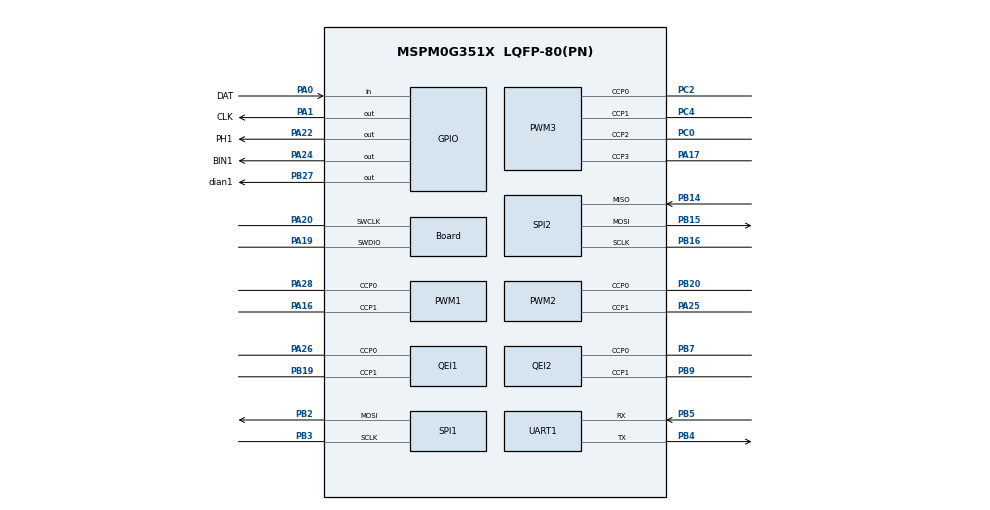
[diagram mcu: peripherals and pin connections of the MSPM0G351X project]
/**
 *
 * @cliArgs --device "MSPM0G351X" --part "Default" --package "LQFP-80(PN)" --product "mspm0_sdk@2.11.00.07"
 * @versions {"tool":"1.28.0+4712"}
 */

/**
 * Import the modules used in this configuration.
 */
const ADC12  = scripting.addModule("/ti/driverlib/ADC12", {}, false);
const ADC121 = ADC12.addInstance();
const GPIO   = scripting.addModule("/ti/driverlib/GPIO", {}, false);
const GPIO1  = GPIO.addInstance();
const GPIO2  = GPIO.addInstance();
const GPIO3  = GPIO.addInstance();
const GPIO4  = GPIO.addInstance();
const GPIO5  = GPIO.addInstance();
const GPIO6  = GPIO.addInstance();
const GPIO7  = GPIO.addInstance();
const GPIO8  = GPIO.addInstance();
const PWM    = scripting.addModule("/ti/driverlib/PWM", {}, false);
const PWM1   = PWM.addInstance();
const PWM2   = PWM.addInstance();
const PWM3   = PWM.addInstance();
const QEI    = scripting.addModule("/ti/driverlib/QEI", {}, false);
const QEI1   = QEI.addInstance();
const QEI2   = QEI.addInstance();
const SPI    = scripting.addModule("/ti/driverlib/SPI", {}, false);
const SPI1   = SPI.addInstance();
const SPI2   = SPI.addInstance();
const SYSCTL = scripting.addModule("/ti/driverlib/SYSCTL");
const UART   = scripting.addModule("/ti/driverlib/UART", {}, false);
const UART1  = UART.addInstance();

/**
 * Write custom configuration values to the imported modules.
 */
const divider9       = system.clockTree["UDIV"];
divider9.divideValue = 2;

const multiplier2         = system.clockTree["PLL_QDIV"];
multiplier2.multiplyValue = 5;

const mux8       = system.clockTree["HSCLKMUX"];
mux8.inputSelect = "HSCLKMUX_SYSPLL0";

ADC121.sampClkDiv                        = "DL_ADC12_CLOCK_DIVIDE_4";
ADC121.samplingOperationMode             = "sequence";
ADC121.endAdd                            = 1;
ADC121.$name                             = "ADC1";
ADC121.sampleMode                        = "DL_ADC12_SAMPLING_SOURCE_MANUAL";
ADC121.adcMem1chansel                    = "DL_ADC12_INPUT_CHAN_4";
ADC121.adcMem1_name                      = "DRC8873_ADC1";
ADC121.adcMem0_name                      = "DRC8873_ADC0";
ADC121.adcPin0Config.hideOutputInversion = scripting.forceWrite(false);
ADC121.adcPin0Config.$name               = "ti_driverlib_gpio_GPIOPinGeneric25";
ADC121.peripheral.$assign                = "ADC1";
ADC121.peripheral.adcPin0.$assign        = "PA15";
ADC121.adcPin4Config.$name               = "ti_driverlib_gpio_GPIOPinGeneric27";

const Board                       = scripting.addModule("/ti/driverlib/Board", {}, false);
Board.peripheral.$assign          = "DEBUGSS";
Board.peripheral.swclkPin.$assign = "PA20";
Board.peripheral.swdioPin.$assign = "PA19";

GPIO1.$name                                 = "TFT";
GPIO1.associatedPins.create(4);
GPIO1.associatedPins[0].assignedPort        = "PORTC";
GPIO1.associatedPins[0].assignedPin         = "8";
GPIO1.associatedPins[0].assignedPortSegment = "Lower";
GPIO1.associatedPins[0].initialValue        = "SET";
GPIO1.associatedPins[0].ioStructure         = "SD";
GPIO1.associatedPins[0].$name               = "TFT_DC";
GPIO1.associatedPins[1].assignedPort        = "PORTC";
GPIO1.associatedPins[1].assignedPin         = "9";
GPIO1.associatedPins[1].assignedPortSegment = "Lower";
GPIO1.associatedPins[1].ioStructure         = "SD";
GPIO1.associatedPins[1].initialValue        = "SET";
GPIO1.associatedPins[1].$name               = "TFT_CS";
GPIO1.associatedPins[2].assignedPort        = "PORTB";
GPIO1.associatedPins[2].assignedPin         = "23";
GPIO1.associatedPins[2].initialValue        = "SET";
GPIO1.associatedPins[2].ioStructure         = "SD";
GPIO1.associatedPins[2].$name               = "TFT_RES";
GPIO1.associatedPins[3].initialValue        = "SET";
GPIO1.associatedPins[3].ioStructure         = "SD";
GPIO1.associatedPins[3].assignedPort        = "PORTA";
GPIO1.associatedPins[3].assignedPin         = "30";
GPIO1.associatedPins[3].$name               = "TFT_BLK";

GPIO2.$name                               = "key";
GPIO2.associatedPins.create(5);
GPIO2.associatedPins[0].$name             = "key0";
GPIO2.associatedPins[0].direction         = "INPUT";
GPIO2.associatedPins[0].assignedPort      = "PORTB";
GPIO2.associatedPins[0].assignedPin       = "29";
GPIO2.associatedPins[0].ioStructure       = "SD";
GPIO2.associatedPins[0].interruptEn       = true;
GPIO2.associatedPins[0].interruptPriority = "1";
GPIO2.associatedPins[0].polarity          = "FALL";
GPIO2.associatedPins[1].$name             = "key1";
GPIO2.associatedPins[1].direction         = "INPUT";
GPIO2.associatedPins[1].ioStructure       = "SD";
GPIO2.associatedPins[1].assignedPort      = "PORTB";
GPIO2.associatedPins[1].assignedPin       = "30";
GPIO2.associatedPins[1].interruptEn       = true;
GPIO2.associatedPins[1].interruptPriority = "1";
GPIO2.associatedPins[1].polarity          = "FALL";
GPIO2.associatedPins[2].$name             = "key2";
GPIO2.associatedPins[2].direction         = "INPUT";
GPIO2.associatedPins[2].ioStructure       = "SD";
GPIO2.associatedPins[2].assignedPort      = "PORTC";
GPIO2.associatedPins[2].assignedPin       = "6";
GPIO2.associatedPins[2].interruptEn       = true;
GPIO2.associatedPins[2].interruptPriority = "1";
GPIO2.associatedPins[2].polarity          = "FALL";
GPIO2.associatedPins[3].$name             = "key3";
GPIO2.associatedPins[3].direction         = "INPUT";
GPIO2.associatedPins[3].ioStructure       = "SD";
GPIO2.associatedPins[3].assignedPort      = "PORTC";
GPIO2.associatedPins[3].assignedPin       = "7";
GPIO2.associatedPins[3].interruptEn       = true;
GPIO2.associatedPins[3].interruptPriority = "1";
GPIO2.associatedPins[3].polarity          = "FALL";
GPIO2.associatedPins[4].$name             = "user_key";
GPIO2.associatedPins[4].direction         = "INPUT";
GPIO2.associatedPins[4].assignedPort      = "PORTB";
GPIO2.associatedPins[4].assignedPin       = "31";
GPIO2.associatedPins[4].interruptEn       = true;
GPIO2.associatedPins[4].interruptPriority = "1";
GPIO2.associatedPins[4].polarity          = "FALL";

GPIO3.$name                          = "imuInt";
GPIO3.associatedPins[0].$name        = "CS";
GPIO3.associatedPins[0].assignedPort = "PORTB";
GPIO3.associatedPins[0].assignedPin  = "13";
GPIO3.associatedPins[0].ioStructure  = "SD";
GPIO3.associatedPins[0].initialValue = "SET";

GPIO4.$name                          = "TB6612";
GPIO4.associatedPins.create(4);
GPIO4.associatedPins[0].$name        = "AIN2";
GPIO4.associatedPins[0].ioStructure  = "SD";
GPIO4.associatedPins[0].assignedPort = "PORTB";
GPIO4.associatedPins[0].assignedPin  = "22";
GPIO4.associatedPins[1].$name        = "AIN1";
GPIO4.associatedPins[1].ioStructure  = "SD";
GPIO4.associatedPins[1].assignedPort = "PORTB";
GPIO4.associatedPins[1].assignedPin  = "28";
GPIO4.associatedPins[2].$name        = "BIN1";
GPIO4.associatedPins[2].ioStructure  = "SD";
GPIO4.associatedPins[2].assignedPort = "PORTA";
GPIO4.associatedPins[2].assignedPin  = "24";
GPIO4.associatedPins[2].pin.$assign  = "PA24";
GPIO4.associatedPins[3].$name        = "BIN2";
GPIO4.associatedPins[3].assignedPort = "PORTA";
GPIO4.associatedPins[3].assignedPin  = "13";

GPIO5.$name                          = "dianci";
GPIO5.associatedPins.create(2);
GPIO5.associatedPins[0].ioStructure  = "SD";
GPIO5.associatedPins[0].$name        = "dian1";
GPIO5.associatedPins[0].assignedPin  = "27";
GPIO5.associatedPins[0].assignedPort = "PORTB";
GPIO5.associatedPins[0].pin.$assign  = "PB27";
GPIO5.associatedPins[1].$name        = "dian2";
GPIO5.associatedPins[1].assignedPort = "PORTB";
GPIO5.associatedPins[1].assignedPin  = "26";

GPIO6.$name                          = "buzzer";
GPIO6.associatedPins[0].$name        = "PIN_0";
GPIO6.associatedPins[0].ioStructure  = "SD";
GPIO6.associatedPins[0].assignedPort = "PORTB";
GPIO6.associatedPins[0].assignedPin  = "1";

GPIO7.$name                          = "DRV8873HPWPT";
GPIO7.associatedPins.create(2);
GPIO7.associatedPins[0].$name        = "PH1";
GPIO7.associatedPins[0].ioStructure  = "SD";
GPIO7.associatedPins[0].assignedPort = "PORTA";
GPIO7.associatedPins[0].pin.$assign  = "PA22";
GPIO7.associatedPins[1].$name        = "PH2";
GPIO7.associatedPins[1].ioStructure  = "SD";
GPIO7.associatedPins[1].assignedPort = "PORTB";
GPIO7.associatedPins[1].assignedPin  = "18";

GPIO8.$name                          = "graySerial";
GPIO8.associatedPins.create(2);
GPIO8.associatedPins[0].$name        = "CLK";
GPIO8.associatedPins[0].initialValue = "SET";
GPIO8.associatedPins[0].assignedPin  = "1";
GPIO8.associatedPins[0].assignedPort = "PORTA";
GPIO8.associatedPins[0].pin.$assign  = "PA1";
GPIO8.associatedPins[1].$name        = "DAT";
GPIO8.associatedPins[1].direction    = "INPUT";
GPIO8.associatedPins[1].assignedPort = "PORTA";
GPIO8.associatedPins[1].assignedPin  = "0";
GPIO8.associatedPins[1].pin.$assign  = "PA0";

PWM1.clockPrescale                      = 8;
PWM1.timerCount                         = 400;
PWM1.$name                              = "TB6612PWM";
PWM1.pwmMode                            = "EDGE_ALIGN_UP";
PWM1.peripheral.$assign                 = "TIMA1";
PWM1.peripheral.ccp0Pin.$assign         = "PA28";
PWM1.peripheral.ccp1Pin.$assign         = "PA16";
PWM1.PWM_CHANNEL_0.$name                = "ti_driverlib_pwm_PWMTimerCC4";
PWM1.PWM_CHANNEL_1.$name                = "ti_driverlib_pwm_PWMTimerCC5";
PWM1.ccp0PinConfig.direction            = scripting.forceWrite("OUTPUT");
PWM1.ccp0PinConfig.hideOutputInversion  = scripting.forceWrite(false);
PWM1.ccp0PinConfig.onlyInternalResistor = scripting.forceWrite(false);
PWM1.ccp0PinConfig.passedPeripheralType = scripting.forceWrite("Digital");
PWM1.ccp0PinConfig.$name                = "ti_driverlib_gpio_GPIOPinGeneric21";
PWM1.ccp1PinConfig.direction            = scripting.forceWrite("OUTPUT");
PWM1.ccp1PinConfig.hideOutputInversion  = scripting.forceWrite(false);
PWM1.ccp1PinConfig.onlyInternalResistor = scripting.forceWrite(false);
PWM1.ccp1PinConfig.passedPeripheralType = scripting.forceWrite("Digital");
PWM1.ccp1PinConfig.$name                = "ti_driverlib_gpio_GPIOPinGeneric22";

PWM2.$name                              = "DRV8873";
PWM2.pwmMode                            = "EDGE_ALIGN_UP";
PWM2.peripheral.ccp0Pin.$assign         = "PB20";
PWM2.peripheral.ccp1Pin.$assign         = "PA25";
PWM2.PWM_CHANNEL_0.$name                = "ti_driverlib_pwm_PWMTimerCC6";
PWM2.PWM_CHANNEL_1.$name                = "ti_driverlib_pwm_PWMTimerCC7";
PWM2.ccp0PinConfig.direction            = scripting.forceWrite("OUTPUT");
PWM2.ccp0PinConfig.hideOutputInversion  = scripting.forceWrite(false);
PWM2.ccp0PinConfig.onlyInternalResistor = scripting.forceWrite(false);
PWM2.ccp0PinConfig.passedPeripheralType = scripting.forceWrite("Digital");
PWM2.ccp0PinConfig.$name                = "ti_driverlib_gpio_GPIOPinGeneric23";
PWM2.ccp1PinConfig.direction            = scripting.forceWrite("OUTPUT");
PWM2.ccp1PinConfig.hideOutputInversion  = scripting.forceWrite(false);
PWM2.ccp1PinConfig.onlyInternalResistor = scripting.forceWrite(false);
PWM2.ccp1PinConfig.passedPeripheralType = scripting.forceWrite("Digital");
PWM2.ccp1PinConfig.$name                = "ti_driverlib_gpio_GPIOPinGeneric24";

PWM3.$name                              = "servo";
PWM3.ccIndex                            = [0,1,2,3];
PWM3.pwmMode                            = "EDGE_ALIGN_UP";
PWM3.clockPrescale                      = 79;
PWM3.timerCount                         = 20000;
PWM3.PWM_CHANNEL_0.$name                = "ti_driverlib_pwm_PWMTimerCC0";
PWM3.PWM_CHANNEL_1.$name                = "ti_driverlib_pwm_PWMTimerCC1";
PWM3.ccp0PinConfig.direction            = scripting.forceWrite("OUTPUT");
PWM3.ccp0PinConfig.hideOutputInversion  = scripting.forceWrite(false);
PWM3.ccp0PinConfig.onlyInternalResistor = scripting.forceWrite(false);
PWM3.ccp0PinConfig.passedPeripheralType = scripting.forceWrite("Digital");
PWM3.ccp0PinConfig.$name                = "ti_driverlib_gpio_GPIOPinGeneric13";
PWM3.ccp1PinConfig.direction            = scripting.forceWrite("OUTPUT");
PWM3.ccp1PinConfig.hideOutputInversion  = scripting.forceWrite(false);
PWM3.ccp1PinConfig.onlyInternalResistor = scripting.forceWrite(false);
PWM3.ccp1PinConfig.passedPeripheralType = scripting.forceWrite("Digital");
PWM3.ccp1PinConfig.$name                = "ti_driverlib_gpio_GPIOPinGeneric14";
PWM3.peripheral.$assign                 = "TIMA0";
PWM3.peripheral.ccp0Pin.$assign         = "PC2";
PWM3.peripheral.ccp1Pin.$assign         = "PC4";
PWM3.peripheral.ccp2Pin.$assign         = "PC0";
PWM3.peripheral.ccp3Pin.$assign         = "PA17";
PWM3.PWM_CHANNEL_2.$name                = "ti_driverlib_pwm_PWMTimerCC2";
PWM3.PWM_CHANNEL_3.$name                = "ti_driverlib_pwm_PWMTimerCC3";
PWM3.ccp2PinConfig.$name                = "ti_driverlib_gpio_GPIOPinGeneric15";
PWM3.ccp3PinConfig.$name                = "ti_driverlib_gpio_GPIOPinGeneric16";

QEI1.$name                              = "AB1";
QEI1.peripheral.$assign                 = "TIMG8";
QEI1.peripheral.ccp0Pin.$assign         = "PA26";
QEI1.peripheral.ccp1Pin.$assign         = "PB19";
QEI1.ccp0PinConfig.hideOutputInversion  = scripting.forceWrite(false);
QEI1.ccp0PinConfig.onlyInternalResistor = scripting.forceWrite(false);
QEI1.ccp0PinConfig.passedPeripheralType = scripting.forceWrite("Digital");
QEI1.ccp0PinConfig.$name                = "ti_driverlib_gpio_GPIOPinGeneric17";
QEI1.ccp1PinConfig.hideOutputInversion  = scripting.forceWrite(false);
QEI1.ccp1PinConfig.onlyInternalResistor = scripting.forceWrite(false);
QEI1.ccp1PinConfig.passedPeripheralType = scripting.forceWrite("Digital");
QEI1.ccp1PinConfig.$name                = "ti_driverlib_gpio_GPIOPinGeneric18";

QEI2.$name                              = "AB2";
QEI2.peripheral.ccp0Pin.$assign         = "PB7";
QEI2.peripheral.ccp1Pin.$assign         = "PB9";
QEI2.ccp0PinConfig.hideOutputInversion  = scripting.forceWrite(false);
QEI2.ccp0PinConfig.onlyInternalResistor = scripting.forceWrite(false);
QEI2.ccp0PinConfig.passedPeripheralType = scripting.forceWrite("Digital");
QEI2.ccp0PinConfig.$name                = "ti_driverlib_gpio_GPIOPinGeneric19";
QEI2.ccp1PinConfig.hideOutputInversion  = scripting.forceWrite(false);
QEI2.ccp1PinConfig.onlyInternalResistor = scripting.forceWrite(false);
QEI2.ccp1PinConfig.passedPeripheralType = scripting.forceWrite("Digital");
QEI2.ccp1PinConfig.$name                = "ti_driverlib_gpio_GPIOPinGeneric20";

SPI1.chipSelect                         = [];
SPI1.frameFormat                        = "MOTO3";
SPI1.$name                              = "TFT_SPI0";
SPI1.sclkPinConfig.direction            = scripting.forceWrite("OUTPUT");
SPI1.sclkPinConfig.onlyInternalResistor = scripting.forceWrite(false);
SPI1.sclkPinConfig.passedPeripheralType = scripting.forceWrite("Digital");
SPI1.sclkPinConfig.$name                = "ti_driverlib_gpio_GPIOPinGeneric0";
SPI1.mosiPinConfig.direction            = scripting.forceWrite("OUTPUT");
SPI1.mosiPinConfig.hideOutputInversion  = scripting.forceWrite(false);
SPI1.mosiPinConfig.onlyInternalResistor = scripting.forceWrite(false);
SPI1.mosiPinConfig.passedPeripheralType = scripting.forceWrite("Digital");
SPI1.mosiPinConfig.$name                = "ti_driverlib_gpio_GPIOPinGeneric1";
SPI1.misoPinConfig.onlyInternalResistor = scripting.forceWrite(false);
SPI1.misoPinConfig.passedPeripheralType = scripting.forceWrite("Digital");
SPI1.misoPinConfig.$name                = "ti_driverlib_gpio_GPIOPinGeneric2";
SPI1.peripheral.sclkPin.$assign         = "PB3";
SPI1.peripheral.mosiPin.$assign         = "PB2";

SPI2.$name                              = "IMU660RC";
SPI2.enableDMAEvent1                    = false;
SPI2.enableDMAEvent2                    = false;
SPI2.frameFormat                        = "MOTO3";
SPI2.sclkPinConfig.direction            = scripting.forceWrite("OUTPUT");
SPI2.sclkPinConfig.onlyInternalResistor = scripting.forceWrite(false);
SPI2.sclkPinConfig.passedPeripheralType = scripting.forceWrite("Digital");
SPI2.sclkPinConfig.$name                = "ti_driverlib_gpio_GPIOPinGeneric9";
SPI2.mosiPinConfig.direction            = scripting.forceWrite("OUTPUT");
SPI2.mosiPinConfig.hideOutputInversion  = scripting.forceWrite(false);
SPI2.mosiPinConfig.onlyInternalResistor = scripting.forceWrite(false);
SPI2.mosiPinConfig.passedPeripheralType = scripting.forceWrite("Digital");
SPI2.mosiPinConfig.$name                = "ti_driverlib_gpio_GPIOPinGeneric10";
SPI2.misoPinConfig.onlyInternalResistor = scripting.forceWrite(false);
SPI2.misoPinConfig.passedPeripheralType = scripting.forceWrite("Digital");
SPI2.misoPinConfig.$name                = "ti_driverlib_gpio_GPIOPinGeneric11";
SPI2.peripheral.sclkPin.$assign         = "PB16";
SPI2.peripheral.mosiPin.$assign         = "PB15";
SPI2.peripheral.misoPin.$assign         = "PB14";

SYSCTL.BORThresh                      = "1";
SYSCTL.validateClkStatus              = true;
SYSCTL.SYSPLL_CLK0En                  = true;
SYSCTL.MCLKSource                     = "HSCLK";
SYSCTL.enableWorkaround_SYSPLL_ERR_01 = false;
SYSCTL.clockTreeEn                    = true;

UART1.enableFIFO                       = true;
UART1.rxFifoThreshold                  = "DL_UART_RX_FIFO_LEVEL_ONE_ENTRY";
UART1.enableDMARX                      = false;
UART1.enableDMATX                      = false;
UART1.$name                            = "blue";
UART1.peripheral.$assign               = "UART1";
UART1.peripheral.rxPin.$assign         = "PB5";
UART1.peripheral.txPin.$assign         = "PB4";
UART1.txPinConfig.direction            = scripting.forceWrite("OUTPUT");
UART1.txPinConfig.hideOutputInversion  = scripting.forceWrite(false);
UART1.txPinConfig.onlyInternalResistor = scripting.forceWrite(false);
UART1.txPinConfig.passedPeripheralType = scripting.forceWrite("Digital");
UART1.txPinConfig.$name                = "ti_driverlib_gpio_GPIOPinGeneric5";
UART1.rxPinConfig.hideOutputInversion  = scripting.forceWrite(false);
UART1.rxPinConfig.onlyInternalResistor = scripting.forceWrite(false);
UART1.rxPinConfig.passedPeripheralType = scripting.forceWrite("Digital");
UART1.rxPinConfig.$name                = "ti_driverlib_gpio_GPIOPinGeneric6";

const ProjectConfig              = scripting.addModule("/ti/project_config/ProjectConfig", {}, false);
ProjectConfig.migrationCondition = true;

/**
 * Pinmux solution for unlocked pins/peripherals. This ensures that minor changes to the automatic solver in a future
 * version of the tool will not impact the pinmux you originally saw.  These lines can be completely deleted in order to
 * re-solve from scratch.
 */
ADC121.peripheral.adcPin4.$suggestSolution   = "PB17";
GPIO1.associatedPins[0].pin.$suggestSolution = "PC8";
GPIO1.associatedPins[1].pin.$suggestSolution = "PC9";
GPIO1.associatedPins[2].pin.$suggestSolution = "PB23";
GPIO1.associatedPins[3].pin.$suggestSolution = "PA30";
GPIO2.associatedPins[0].pin.$suggestSolution = "PB29";
GPIO2.associatedPins[1].pin.$suggestSolution = "PB30";
GPIO2.associatedPins[2].pin.$suggestSolution = "PC6";
GPIO2.associatedPins[3].pin.$suggestSolution = "PC7";
GPIO2.associatedPins[4].pin.$suggestSolution = "PB31";
GPIO3.associatedPins[0].pin.$suggestSolution = "PB13";
GPIO4.associatedPins[0].pin.$suggestSolution = "PB22";
GPIO4.associatedPins[1].pin.$suggestSolution = "PB28";
GPIO4.associatedPins[3].pin.$suggestSolution = "PA13";
GPIO5.associatedPins[1].pin.$suggestSolution = "PB26";
GPIO6.associatedPins[0].pin.$suggestSolution = "PB1";
GPIO7.associatedPins[1].pin.$suggestSolution = "PB18";
PWM2.peripheral.$suggestSolution             = "TIMG12";
QEI2.peripheral.$suggestSolution             = "TIMG9";
SPI1.peripheral.$suggestSolution             = "SPI0";
SPI1.peripheral.misoPin.$suggestSolution     = "PA10";
SPI2.peripheral.$suggestSolution             = "SPI1";
